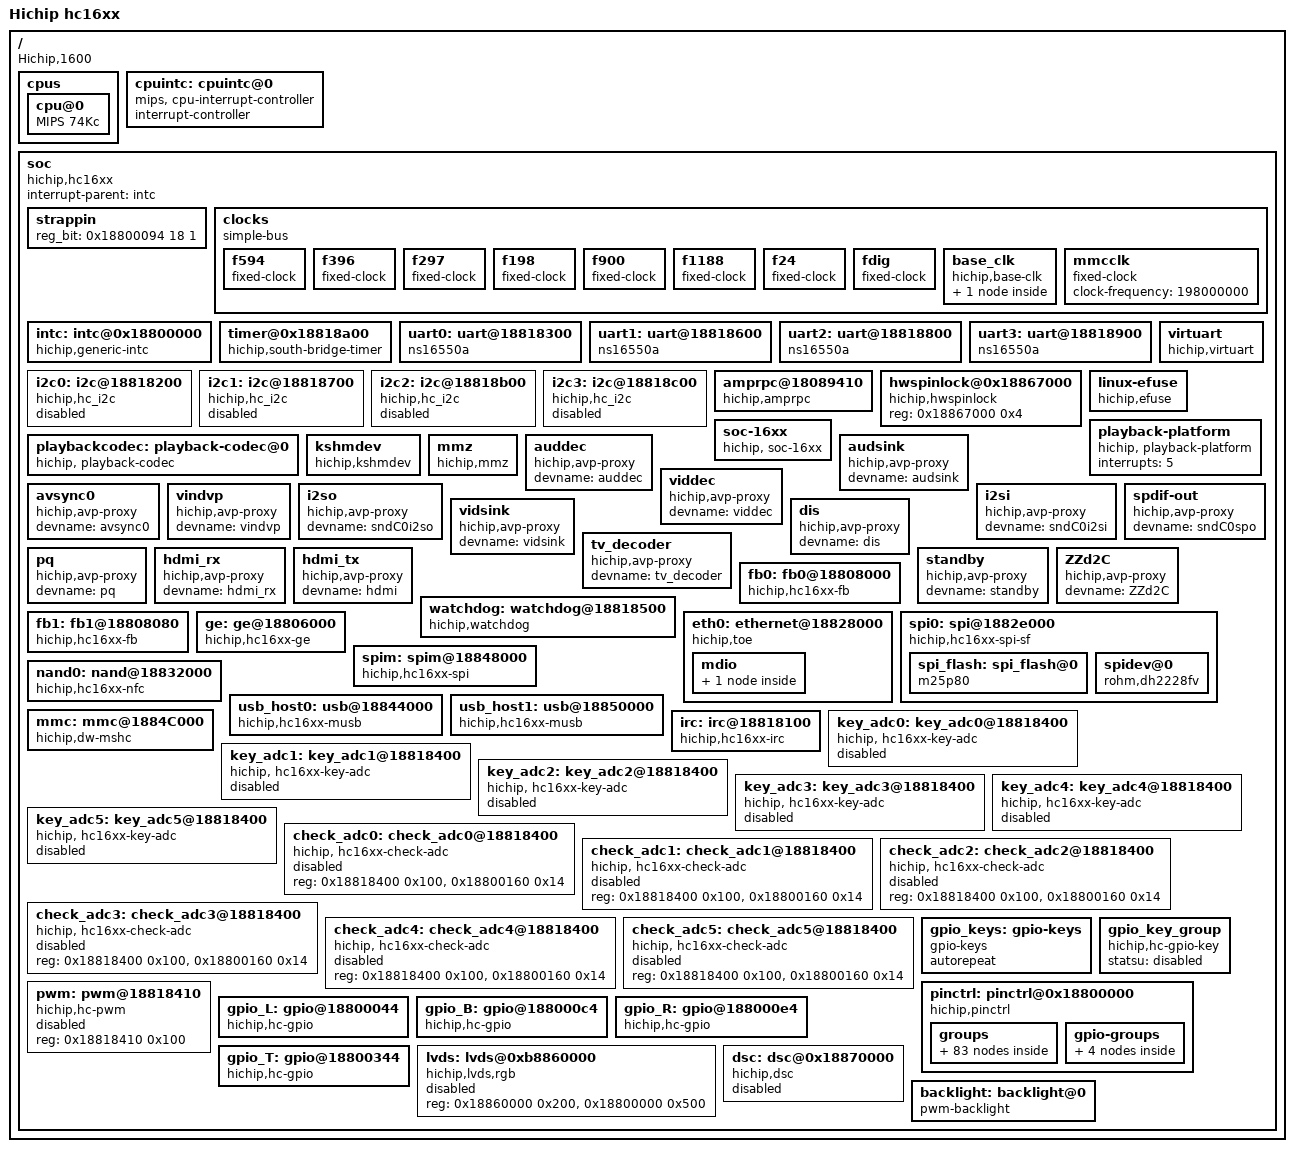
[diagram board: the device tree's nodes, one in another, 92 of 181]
/dts-v1/;

#include <dt-bindings/gpio/gpio.h>

#define MCPU_DIG_PLL_CLK 900

/{
	model = "Hichip hc16xx";
	compatible = "Hichip,1600";
	#address-cells = <1>;
	#size-cells = <1>;
	interrupt-parent = <&cpuintc>;

	cpus: cpus {
		#address-cells = <1>;
		#size-cells = <0>;
		cpu@0 {
			device_type = "cpu";
			compatible = "MIPS 74Kc";
			reg = <0>;
			clocks = <&cpu_clk>;
			/*
			 * 0 : 594M
			 * 1 : 396M
			 * 2 : 297M
			 * 3 : 198M
			 * 4 : 900M
			 * 5 : 1188M
			 * 6 : 24M
			 * 7 : CPU dig pll clk
			 */
			clock = <4>;
			mcpu-dig-pll-clk = <MCPU_DIG_PLL_CLK>;
		};
	};

	cpuintc: cpuintc@0 {
		#address-cells = <0>;
		#interrupt-cells = <1>;
		interrupt-controller;
		compatible = "mips, cpu-interrupt-controller";
	};

	

soc {
	#address-cells = <1>;
	#size-cells = <1>;
	device_type = "soc";
	ranges;
	compatible = "hichip,hc16xx", "simple-bus";
	interrupt-parent=<&intc>;

	strappin:strappin {
		device_type = "hichip,platform-setup-setbit";
		reg_bit = <0x18800094 18 1>;
	};

	clocks {
		#address-cells = <1>;
		#size-cells = <1>;
		compatible = "simple-bus";
		ranges;

		f594: f594 {
			#clock-cells = <0>;
			compatible = "fixed-clock";
			clock-frequency = <594000000>;
			clock-output-names="f594";
		};

		f396: f396 {
			#clock-cells = <0>;
			compatible = "fixed-clock";
			clock-frequency = <396000000>;
			clock-output-names="f396";
		};
		f297: f297 {
			#clock-cells = <0>;
			compatible = "fixed-clock";
			clock-frequency = <297000000>;
			clock-output-names="f297";
		};
		f198: f198 {
			#clock-cells = <0>;
			compatible = "fixed-clock";
			clock-frequency = <198000000>;
			clock-output-names="f198";
		};
		f900: f900 {
			#clock-cells = <0>;
			compatible = "fixed-clock";
			clock-frequency = <900000000>;
			clock-output-names="f900";
		};
		f1188: f1188 {
			#clock-cells = <0>;
			compatible = "fixed-clock";
			clock-frequency = <1188000000>;
			clock-output-names="f1188";
		};

		f24: f24 {
			#clock-cells = <0>;
			compatible = "fixed-clock";
			clock-frequency = <24000000>;
			clock-output-names="f24";
		};

		fdig: fdig {
			#clock-cells = <0>;
			compatible = "fixed-clock";
			clock-frequency = <(MCPU_DIG_PLL_CLK * 1000000)>;
			clock-output-names="fdig";
		};

		base_clk {
			compatible = "hichip,base-clk";
			#address-cells = <1>;
			#size-cells = <1>;
			ranges;

			cpu_clk: cpu_clk@18800070 {
				#clock-cells = <0>;
				compatible = "hichip,cpu-clk";
				reg = <0x18800074 0x4>, <0x18800070 0x4>;

				ctrl_shift = /bits/ 8 <8>;
				info_shift = /bits/ 8 <8>;
				trig_shift = /bits/ 8 <22>;
				width = /bits/ 8 <3>;

				clocks = <&f594>, <&f396>, <&f297>, <&f198>,
				       <&f900>, <&f1188>, <&f24>, <&fdig>;
				clock-output-names = "cpu_clk";
			};
		};

		mmcclk: mmcclk {
			#clock-cells = <0>;
			compatible = "fixed-clock";
			//clock-freq-min-max = <200000 150000000>;
			// clock-frequency = <298000000>;
			 clock-frequency = <198000000>;
			//clock-frequency = <150000000>;
			 //clock-frequency = <99000000>;
			 //clock-frequency = <49500000>;
		};
	};

	intc: intc@0x18800000 {
		compatible="hichip,generic-intc";
		interrupt-controller;
		#interrupt-cells=<1>;
		max-irqs = <96>;
		interrupt-parent = <&cpuintc>;
		interrupts = <3 2>;
		reg = <0x18800028 0x18>,
		      <0x18800030 0x18>,
		      <0x18800038 0x18>,
		      <0x18800020 0x18>;
	};

	timer@0x18818a00 {
		compatible = "hichip,south-bridge-timer";
		reg = <0x18818a00 0x100>;
		interrupts = <22>;
		clock-frequency = <24000000>;
	};

	uart0: uart@18818300 {
		compatible = "ns16550a";
		reg = <0x18818300 0x0C>;
		interrupts = <16>;
		clock-frequency = <1843200>;
		current-speed = <115200>;
		reg-offset = <0>;
		reg-shift = <0>;
		fifo-size = <16>;
		reg-io-width = <1>;
		device_type = "hichip,platform-setup-setbit";
		reg_bit = <0x18800060 16 0>, <0x18800094 18 1>;
	};

	uart1: uart@18818600 {
		compatible = "ns16550a";
		reg = <0x18818600 0x0C>;
		interrupts = <17>;
		clock-frequency = <1843200>;
		current-speed = <115200>;
		reg-offset = <0>;
		reg-shift = <0>;
		fifo-size = <16>;
		reg-io-width = <1>;
		device_type = "hichip,platform-setup-setbit";
		reg_bit = <0x18800060 17 0>;
	};

	uart2: uart@18818800 {
		compatible = "ns16550a";
		reg = <0x18818800 0x0C>;
		interrupts = <54>;
		clock-frequency = <1843200>;
		current-speed = <115200>;
		reg-offset = <0>;
		reg-shift = <0>;
		fifo-size = <16>;
		reg-io-width = <1>;
		device_type = "hichip,platform-setup-setbit";
		reg_bit = <0x18800064 11 0>;
	};

	uart3: uart@18818900 {
		compatible = "ns16550a";
		reg = <0x18818900 0x0C>;
		interrupts = <55>;
		clock-frequency = <1843200>;
		current-speed = <115200>;
		reg-offset = <0>;
		reg-shift = <0>;
		fifo-size = <16>;
		reg-io-width = <1>;
		device_type = "hichip,platform-setup-setbit";
		reg_bit = <0x18800064 11 0>;
	};

	i2c0: i2c@18818200 {
     		compatible = "hichip,hc_i2c";
		reg = <0x18818200 0x100>;
		master-mode = <1>;
		baud_speed = <100000>;
		interrupts = <18>;
		status = "disabled";
	};
	
	i2c1: i2c@18818700 {
     		compatible = "hichip,hc_i2c";
		reg = <0x18818700 0x100>;
		master-mode = <1>;
		baud_speed = <100000>;
		interrupts = <25>;
		status = "disabled";
	};

	i2c2: i2c@18818b00 {
     		compatible = "hichip,hc_i2c";
		reg = <0x18818b00 0x100>;
		master-mode = <1>;
		baud_speed = <100000>;
		interrupts = <26>;
		status = "disabled";
	};

	i2c3: i2c@18818c00 {                 
                compatible = "hichip,hc_i2c";
                reg = <0x18818c00 0x100>;    
                master-mode = <1>;           
                baud_speed = <100000>;       
		interrupts = <43>;
                status = "disabled";         
         };                                   

	amprpc@18089410 {
		compatible = "hichip,amprpc";
		interrupts = <66>;
		reg = <0x18800800 0x20>,
		      <0x18800820 0x20>,
		      <0x18800840 0x20>,
		      <0x18800860 0x20>,
		      <0x18800880 0x20>,
		      <0x188008a0 0x20>,
		      <0x188008c0 0x20>,
		      <0x188008e0 0x20>,
		      <0x18866800 0x20>,
		      <0x18866820 0x20>,
		      <0x18866840 0x20>,
		      <0x18866860 0x20>,
		      <0x18866880 0x20>,
		      <0x188668a0 0x20>,
		      <0x188668c0 0x20>,
		      <0x188668e0 0x20>;
	};


	hwspinlock@0x18867000 {
		compatible = "hichip,hwspinlock";
		reg = <0x18867000 0x4>;
	};

	virtuart {
		compatible = "hichip,virtuart";
	};

	linux-efuse {
		compatible = "hichip,efuse";
	};

	soc-16xx {
		compatible = "hichip, soc-16xx";
	};

	playback-platform {
		compatible = "hichip, playback-platform";
		interrupts = <5>;
	};

	playbackcodec: playback-codec@0 {
		compatible = "hichip, playback-codec";
	};
	/* for alsa end */

	kshmdev {
		compatible = "hichip,kshmdev";
	};

	mmz {
		compatible = "hichip,mmz";
	};

	/* for avp-proxy device driver start */
	auddec {
		compatible = "hichip,avp-proxy";
		devname = "auddec";
	};

	audsink {
		compatible = "hichip,avp-proxy";
		devname = "audsink";
	};

	viddec {
		compatible = "hichip,avp-proxy";
		devname = "viddec";
	};

	avsync0 {
		compatible = "hichip,avp-proxy";
		devname = "avsync0";
	};

	vindvp {
		compatible = "hichip,avp-proxy";
		devname = "vindvp";
	};

	i2so {
		compatible = "hichip,avp-proxy";
		devname = "sndC0i2so";
	};

	i2si {
		compatible = "hichip,avp-proxy";
		devname = "sndC0i2si";
	};

	spdif-out {
		compatible = "hichip,avp-proxy";
		devname = "sndC0spo";
	};

	vidsink {
		compatible = "hichip,avp-proxy";
		devname = "vidsink";
	};

	dis {
		compatible = "hichip,avp-proxy";
		devname = "dis";
	};

	tv_decoder {
		compatible = "hichip,avp-proxy";
		devname = "tv_decoder";
	};
	pq {
		compatible = "hichip,avp-proxy";
		devname = "pq";
	};

	hdmi_rx {
		compatible = "hichip,avp-proxy";
		devname = "hdmi_rx";
	};

	hdmi_tx {
		compatible = "hichip,avp-proxy";
		devname = "hdmi";
	};

	standby {
		compatible = "hichip,avp-proxy";
		devname = "standby";
	};

	ZZd2C {
		compatible = "hichip,avp-proxy";
		devname = "ZZd2C";
	};

	/* for avp-proxy device driver end */

	watchdog: watchdog@18818500 {
		compatible = "hichip,watchdog";
		reg = <0x18818500 0x0A>;
		interrupts = <23>;
		timeout-sec = <30>;
	};


	fb0: fb0@18808000 {
		compatible = "hichip,hc16xx-fb";
	};

	fb1: fb1@18808080 {
		compatible = "hichip,hc16xx-fb";
	};

    ge: ge@18806000 {
        compatible = "hichip,hc16xx-ge";
        reg = <0x18806000 0x2000>, <0x18800000 0x1000>;
        interrupts = <4>;
        cmdq_buf_size = <0x3c000>;
        status = "okay";
    };

	eth0: ethernet@18828000 {
		compatible = "hichip,toe";
		device_type = "network";
		model = "HiChip TOE";
		reg = <0x18828000 0x2000 0x18800000 0x4>;
		interrupts = <14>;
		rx-csum-enable = <1>;
		tx-csum-enable = <1>;
		phy-mode = "rmii";
		phy-reversemii = <0>;
		phy-handle = <&phy1>;

		mdio {
			#address-cells = <1>;
			#size-cells = <0>;
			status = "okay";
			phy1: ethernet-phy@1 {
				reg = <1>;
				device_type = "ethernet-phy";
			};
		};
	};

	spi0: spi@1882e000 {
		#address-cells = <1>;
		#size-cells = <0>;
		compatible = "hichip,hc16xx-spi-sf";
		reg = <0x1882e000 0xe0>, <0x1f000000 0x1000>, <0x1f000000 0x1000>;
		num-cs = <2>;
		interrupts = <35>;
		sclk = <50000000>;
		dma-mode = <1>;
		pinctrl-names = "active";
		pinctrl-0 = <&pctl_sf>;

		spi_flash: spi_flash@0 {
			#address-cells = <1>;
			#size-cells = <1>;
			compatible = "m25p80";
			reg = <0>;
			spi-max-frequency = <100000000>;
		};

		spidev@0 {
			compatible = "rohm,dh2228fv";
			reg = <1>;
			spi-max-frequency = <100000000>;
		};
	};


	spim: spim@18848000 {
		compatible = "hichip,hc16xx-spi";
		reg = <0x18848000 0x100>;
		clk_ratio = <4>;
		transfer-mode = <0>;
		dma-mode = <1>;
		cs-pin = <49>;
	};

	nand0: nand@18832000 {
		compatible = "hichip,hc16xx-nfc";
		reg = <0x18832000 0x60>;
		interrupts = <48>;
		scrambling = <0>;
		nand-on-flash-bbt;
		nand-ecc-mode = "hw";
		nand-ecc-algo = "bch";
	};

	usb_host0: usb@18844000 {  // usb_host0 / usb_peripheral0
		compatible = "hichip,hc16xx-musb";
		reg = <0x18844000 0x1000>;
		interrupts = <53>,<52>;
		interrupt-names = "mc","dma";
		dr_mode = "host";  // host/peripheral
		index_num = <0>;
		ctrl_base = <0x18800000>;
	};
	
	usb_host1: usb@18850000 {  // usb_host1/ usb_peripheral1
		compatible = "hichip,hc16xx-musb";
		reg = <0x18850000 0x1000>;
		interrupts = <51>,<50>;
		interrupt-names = "mc","dma";
		dr_mode = "host";
		index_num = <1>;
		ctrl_base = <0x18800000>;
	};

	mmc: mmc@1884C000 {
		compatible = "hichip,dw-mshc";
		// compatible = "snps,dw-mshc";
		reg = <0x1884C000 0x2000>;
		card-detect-delay = <200>;
		clocks = <&mmcclk>, <&mmcclk>;
		clock-names = "biu", "ciu";
		interrupts = <10>;
	};

	irc: irc@18818100 {
		compatible = "hichip,hc16xx-irc";
		reg = <0x18818100 0x60>;
		interrupts = <19>;
	};

	key_adc0: key_adc0@18818400 {
		compatible = "hichip, hc16xx-key-adc";
		reg = <0x18818400 0x100>, <0x18800160 0x14>;
		interrupts = <37>;
		status = "disabled";
	};

	key_adc1: key_adc1@18818400 {
		compatible = "hichip, hc16xx-key-adc";
		reg = <0x18818400 0x100>, <0x18800160 0x14>;
		interrupts = <37>;
		status = "disabled";
	};

	key_adc2: key_adc2@18818400 {
		compatible = "hichip, hc16xx-key-adc";
		reg = <0x18818400 0x100>, <0x18800160 0x14>;
		interrupts = <37>;
		status = "disabled";
	};

	key_adc3: key_adc3@18818400 {
		compatible = "hichip, hc16xx-key-adc";
		reg = <0x18818400 0x100>, <0x18800160 0x14>;
		interrupts = <37>;
		status = "disabled";
	};

	key_adc4: key_adc4@18818400 {
		compatible = "hichip, hc16xx-key-adc";
		reg = <0x18818400 0x100>, <0x18800160 0x14>;
		interrupts = <37>;
		status = "disabled";
	};

	key_adc5: key_adc5@18818400 {
		compatible = "hichip, hc16xx-key-adc";
		reg = <0x18818400 0x100>, <0x18800160 0x14>;
		interrupts = <37>;
		status = "disabled";
	};

	check_adc0: check_adc0@18818400 {
		compatible = "hichip, hc16xx-check-adc";
		reg = <0x18818400 0x100>, <0x18800160 0x14>;
		status = "disabled";
	};

	check_adc1: check_adc1@18818400 {
		compatible = "hichip, hc16xx-check-adc";
		reg = <0x18818400 0x100>, <0x18800160 0x14>;
		status = "disabled";
	};

	check_adc2: check_adc2@18818400 {
		compatible = "hichip, hc16xx-check-adc";
		reg = <0x18818400 0x100>, <0x18800160 0x14>;
		status = "disabled";
	};

	check_adc3: check_adc3@18818400 {
		compatible = "hichip, hc16xx-check-adc";
		reg = <0x18818400 0x100>, <0x18800160 0x14>;
		status = "disabled";
	};

	check_adc4: check_adc4@18818400 {
		compatible = "hichip, hc16xx-check-adc";
		reg = <0x18818400 0x100>, <0x18800160 0x14>;
		status = "disabled";
	};

	check_adc5: check_adc5@18818400 {
		compatible = "hichip, hc16xx-check-adc";
		reg = <0x18818400 0x100>, <0x18800160 0x14>;
		status = "disabled";
	};

	gpio_keys: gpio-keys {
		compatible = "gpio-keys";
		#address-cells = <1>;
		#size-cells = <0>;
		autorepeat;
	};

	pwm: pwm@18818410 {
		compatible = "hichip,hc-pwm";
		reg = <0x18818410 0x100>;
		status = "disabled";
	};

	gpio_key_group: gpio_key_group {
		compatible = "hichip,hc-gpio-key";
		statsu = "disabled";
	};

	pinctrl: pinctrl@0x18800000 {
		compatible = "hichip,pinctrl";
		reg = <0x18800000 0x820>;
		pins =
			"GPIO_L_00",	// pin 0
			"GPIO_L_01",	// pin 1
			"GPIO_L_02",	// pin 2
			"GPIO_L_03",	// pin 3
			"GPIO_L_04",	// pin 4
			"GPIO_L_05",	// pin 5
			"GPIO_L_06",	// pin 6
			"GPIO_L_07",	// pin 7
			"GPIO_L_08",	// pin 8
			"GPIO_L_09",	// pin 9
			"GPIO_L_10",	// pin 10
			"GPIO_L_11",	// pin 11
			"GPIO_L_12",	// pin 12
			"GPIO_L_13",	// pin 13
			"GPIO_L_14",	// pin 14
			"GPIO_L_15",	// pin 15
			"GPIO_L_16",	// pin 16
			"GPIO_L_17",	// pin 17
			"GPIO_L_18",	// pin 18
			"GPIO_L_19",	// pin 19
			"GPIO_L_20",	// pin 20
			"GPIO_L_21",	// pin 21
			"GPIO_L_22",	// pin 22
			"GPIO_L_23",	// pin 23
			"GPIO_L_24",	// pin 24
			"GPIO_L_25",	// pin 25
			"GPIO_L_26",	// pin 26
			"GPIO_L_27",	// pin 27
			"GPIO_L_28",	// pin 28
			"GPIO_L_29",	// pin 29
			"GPIO_L_30",	// pin 30
			"GPIO_L_31",	// pin 31
			"GPIO_B_00",	// pin 32
			"GPIO_B_01",	// pin 33
			"GPIO_B_02",	// pin 34
			"GPIO_B_03",	// pin 35
			"GPIO_B_04",	// pin 36
			"GPIO_B_05",	// pin 37
			"GPIO_B_06",	// pin 38
			"GPIO_B_07",	// pin 39
			"GPIO_B_08",	// pin 40
			"GPIO_B_09",	// pin 41
			"GPIO_B_10",	// pin 42
			"GPIO_B_11",	// pin 43
			"GPIO_B_12",	// pin 44
			"GPIO_B_13",	// pin 45
			"GPIO_B_14",	// pin 46
			"GPIO_B_15",	// pin 47
			"GPIO_B_16",	// pin 48
			"GPIO_B_17",	// pin 49
			"GPIO_B_18",	// pin 50
			"GPIO_B_19",	// pin 51
			"GPIO_B_20",	// pin 52
			"GPIO_B_21",	// pin 53
			"GPIO_B_22",	// pin 54
			"GPIO_B_23",	// pin 55
			"GPIO_B_24",	// pin 56
			"GPIO_B_25",	// pin 57
			"GPIO_B_26",	// pin 58
			"GPIO_B_27",	// pin 59
			"GPIO_B_28",	// pin 60
			"GPIO_B_29",	// pin 61
			"GPIO_B_30",	// pin 62
			"GPIO_B_31",	// pin 63
			"GPIO_R_00",	// pin 64
			"GPIO_R_01",	// pin 65
			"GPIO_R_02",	// pin 66
			"GPIO_R_03",	// pin 67
			"GPIO_R_04",	// pin 68
			"GPIO_R_05",	// pin 69
			"GPIO_R_06",	// pin 70
			"GPIO_R_07",	// pin 71
			"GPIO_R_08",	// pin 72
			"GPIO_R_09",	// pin 73
			"GPIO_R_10",	// pin 74
			"GPIO_R_11",	// pin 75
			"GPIO_R_12",	// pin 76
			"GPIO_R_13",	// pin 77
			"GPIO_R_14",	// pin 78
			"GPIO_R_15",	// pin 79
			"GPIO_R_16",	// pin 80
			"GPIO_R_17",	// pin 81
			"GPIO_R_18",	// pin 82
			"GPIO_R_19",	// pin 83
			"GPIO_R_20",	// pin 84
			"GPIO_R_21",	// pin 85
			"GPIO_R_22",	// pin 86
			"GPIO_R_23",	// pin 87
			"GPIO_R_24",	// pin 88
			"GPIO_R_25",	// pin 89
			"GPIO_R_26",	// pin 90
			"GPIO_R_27",	// pin 91
			"GPIO_R_28",	// pin 92
			"GPIO_R_29",	// pin 93
			"GPIO_R_30",	// pin 94
			"GPIO_R_31",	// pin 95
			"GPIO_T_00",	// pin 96
			"GPIO_T_01",	// pin 97
			"GPIO_T_02",	// pin 98
			"GPIO_T_03",	// pin 99
			"GPIO_T_04",	// pin 100
			"GPIO_T_05",	// pin 101
			"GPIO_T_06",	// pin 102
			"GPIO_T_07",	// pin 103
			"GPIO_T_08",	// pin 104
			"GPIO_T_09",	// pin 105
			"GPIO_T_10",	// pin 106
			"GPIO_T_11",	// pin 107
			"GPIO_T_12",	// pin 108
			"GPIO_T_13",	// pin 109
			"GPIO_T_14",	// pin 110
			"GPIO_T_15",	// pin 111
			"GPIO_T_16",	// pin 112
			"GPIO_T_17",	// pin 113
			"GPIO_T_18",	// pin 114
			"GPIO_T_19",	// pin 115
			"GPIO_T_20",	// pin 116
			"GPIO_T_21",	// pin 117
			"GPIO_T_22",	// pin 118
			"GPIO_T_23",	// pin 119
			"GPIO_T_24",	// pin 120
			"GPIO_T_25",	// pin 121
			"GPIO_T_26",	// pin 122
			"GPIO_T_27",	// pin 123
			"GPIO_T_28",	// pin 124
			"GPIO_T_29",	// pin 125
			"GPIO_T_30",	// pin 126
			"GPIO_T_31";	// pin 127

		groups {
			GPIO_L_00 {
				name = "GPIO_L_00";
				pins = <0>;
				reg-offset = <0x4a0>;
			};
			GPIO_L_01 {
				name = "GPIO_L_01";
				pins = <1>;
				reg-offset = <0x4a1>;
			};
			GPIO_L_02 {
				name = "GPIO_L_02";
				pins = <2>;
				reg-offset = <0x4a2>;
			};
			GPIO_L_03 {
				name = "GPIO_L_03";
				pins = <3>;
				reg-offset = <0x4a3>;
			};
			GPIO_L_04 {
				name = "GPIO_L_04";
				pins = <4>;
				reg-offset = <0x4a4>;
			};
			GPIO_L_05 {
				name = "GPIO_L_05";
				pins = <5>;
				reg-offset = <0x4a5>;
			};
			GPIO_L_06 {
				name = "GPIO_L_06";
				pins = <6>;
				reg-offset = <0x4a6>;
			};
			GPIO_L_07 {
				name = "GPIO_L_07";
				pins = <7>;
				reg-offset = <0x4a7>;
			};
			GPIO_L_08 {
				name = "GPIO_L_08";
				pins = <8>;
				reg-offset = <0x4a8>;
			};
			GPIO_L_09 {
				name = "GPIO_L_09";
				pins = <9>;
				reg-offset = <0x4a9>;
			};
			GPIO_L_10 {
				name = "GPIO_L_10";
				pins = <10>;
				reg-offset = <0x4aa>;
			};
			GPIO_L_11 {
				name = "GPIO_L_11";
				pins = <11>;
				reg-offset = <0x4ab>;
			};
			GPIO_L_12 {
				name = "GPIO_L_12";
				pins = <12>;
				reg-offset = <0x4ac>;
			};
			GPIO_L_13 {
				name = "GPIO_L_13";
				pins = <13>;
				reg-offset = <0x4ad>;
			};
			GPIO_L_14 {
				name = "GPIO_L_14";
				pins = <14>;
				reg-offset = <0x4ae>;
			};
			GPIO_L_15 {
				name = "GPIO_L_15";
				pins = <15>;
				reg-offset = <0x4af>;
			};
			GPIO_L_16 {
				name = "GPIO_L_16";
				pins = <16>;
				reg-offset = <0x4b0>;
			};
			GPIO_L_17 {
				name = "GPIO_L_17";
				pins = <17>;
				reg-offset = <0x4b1>;
			};
			GPIO_L_18 {
				name = "GPIO_L_18";
				pins = <18>;
				reg-offset = <0x4b2>;
			};
			GPIO_L_19 {
				name = "GPIO_L_19";
				pins = <19>;
				reg-offset = <0x4b3>;
			};
			GPIO_L_20 {
				name = "GPIO_L_20";
				pins = <20>;
				reg-offset = <0x4b4>;
			};

			GPIO_B_00 {
				name = "GPIO_B_00";
				pins = <32>;
				reg-offset = <0x4e0>;
			};
			GPIO_B_01 {
				name = "GPIO_B_01";
				pins = <33>;
				reg-offset = <0x4e1>;
			};
			GPIO_B_02 {
				name = "GPIO_B_02";
				pins = <34>;
				reg-offset = <0x4e2>;
			};
			GPIO_B_03 {
				name = "GPIO_B_03";
				pins = <35>;
				reg-offset = <0x4e3>;
			};
			GPIO_B_04 {
				name = "GPIO_B_04";
				pins = <36>;
				reg-offset = <0x4e4>;
			};
			GPIO_B_05 {
				name = "GPIO_B_05";
				pins = <37>;
				reg-offset = <0x4e5>;
			};
			GPIO_B_06 {
				name = "GPIO_B_06";
				pins = <38>;
				reg-offset = <0x4e6>;
			};
			GPIO_B_07 {
				name = "GPIO_B_07";
				pins = <39>;
				reg-offset = <0x4e7>;
			};
			GPIO_B_08 {
				name = "GPIO_B_08";
				pins = <40>;
				reg-offset = <0x4e8>;
			};
			GPIO_B_09 {
				name = "GPIO_B_09";
				pins = <41>;
				reg-offset = <0x4e9>;
			};
			GPIO_B_10 {
				name = "GPIO_B_10";
				pins = <42>;
				reg-offset = <0x4ea>;
			};
			GPIO_B_11 {
				name = "GPIO_B_11";
				pins = <43>;
				reg-offset = <0x4eb>;
			};
			GPIO_B_12 {
				name = "GPIO_B_12";
				pins = <44>;
				reg-offset = <0x4ec>;
			};
			GPIO_B_13 {
				name = "GPIO_B_13";
				pins = <45>;
				reg-offset = <0x4ed>;
			};
			GPIO_B_14 {
				name = "GPIO_B_14";
				pins = <46>;
				reg-offset = <0x4ee>;
			};
			GPIO_B_15 {
				name = "GPIO_B_15";
				pins = <47>;
				reg-offset = <0x4ef>;
			};
			GPIO_B_16 {
				name = "GPIO_B_16";
				pins = <48>;
				reg-offset = <0x4f0>;
			};
			GPIO_B_17 {
				name = "GPIO_B_17";
				pins = <49>;
				reg-offset = <0x4f1>;
			};
			GPIO_B_18 {
				name = "GPIO_B_18";
				pins = <50>;
				reg-offset = <0x4f2>;
			};
			GPIO_B_19 {
				name = "GPIO_B_19";
				pins = <51>;
				reg-offset = <0x4f3>;
			};
			GPIO_B_20 {
				name = "GPIO_B_20";
				pins = <52>;
				reg-offset = <0x4f4>;
			};
			GPIO_B_21 {
				name = "GPIO_B_21";
				pins = <53>;
				reg-offset = <0x4f5>;
			};
			GPIO_B_22 {
				name = "GPIO_B_22";
				pins = <54>;
				reg-offset = <0x4f6>;
			};
			GPIO_B_23 {
				name = "GPIO_B_23";
				pins = <55>;
				reg-offset = <0x4f7>;
			};
			GPIO_B_24 {
				name = "GPIO_B_24";
				pins = <56>;
				reg-offset = <0x4f8>;
			};
			GPIO_R_00 {
				name = "GPIO_R_00";
				pins = <64>;
				reg-offset = <0x520>;
			};
			GPIO_R_01 {
				name = "GPIO_R_01";
				pins = <65>;
				reg-offset = <0x521>;
			};
			GPIO_R_02 {
				name = "GPIO_R_02";
				pins = <66>;
				reg-offset = <0x522>;
			};
			GPIO_R_03 {
				name = "GPIO_R_03";
				pins = <67>;
				reg-offset = <0x523>;
			};
			GPIO_R_04 {
				name = "GPIO_R_04";
				pins = <68>;
				reg-offset = <0x524>;
			};
			GPIO_R_05 {
				name = "GPIO_R_05";
				pins = <69>;
				reg-offset = <0x525>;
			};
			GPIO_R_06 {
				name = "GPIO_R_06";
				pins = <70>;
				reg-offset = <0x526>;
			};
			GPIO_R_07 {
				name = "GPIO_R_07";
				pins = <71>;
				reg-offset = <0x527>;
			};
			GPIO_R_08 {
				name = "GPIO_R_08";
				pins = <72>;
				reg-offset = <0x528>;
			};
			GPIO_R_09 {
				name = "GPIO_R_09";
				pins = <73>;
				reg-offset = <0x529>;
			};
			GPIO_R_10 {
				name = "GPIO_R_10";
				pins = <74>;
				reg-offset = <0x52a>;
			};
			GPIO_T_00 {
				name = "GPIO_T_00";
				pins = <96>;
				reg-offset = <0x560>;
			};
			GPIO_T_01 {
				name = "GPIO_T_01";
				pins = <97>;
				reg-offset = <0x561>;
			};
			GPIO_T_02 {
				name = "GPIO_T_02";
				pins = <98>;
				reg-offset = <0x562>;
			};
			GPIO_T_03 {
				name = "GPIO_T_03";
				pins = <99>;
				reg-offset = <0x563>;
			};
			GPIO_T_04 {
				name = "GPIO_T_04";
				pins = <100>;
				reg-offset = <0x564>;
			};
			GPIO_T_05 {
				name = "GPIO_T_05";
				pins = <101>;
				reg-offset = <0x565>;
			};
			GPIO_T_06 {
				name = "GPIO_T_06";
				pins = <102>;
				reg-offset = <0x566>;
			};
			GPIO_T_07 {
				name = "GPIO_T_07";
				pins = <103>;
				reg-offset = <0x567>;
			};
			GPIO_T_08 {
				name = "GPIO_T_08";
				pins = <104>;
				reg-offset = <0x568>;
			};
			GPIO_T_09 {
				name = "GPIO_T_09";
				pins = <105>;
				reg-offset = <0x569>;
			};
			GPIO_T_10 {
				name = "GPIO_T_10";
				pins = <106>;
				reg-offset = <0x56a>;
			};
			GPIO_T_11 {
				name = "GPIO_T_11";
				pins = <107>;
				reg-offset = <0x56b>;
			};
			GPIO_T_12 {
				name = "GPIO_T_12";
				pins = <108>;
				reg-offset = <0x56c>;
			};
			GPIO_T_13 {
				name = "GPIO_T_13";
				pins = <109>;
				reg-offset = <0x56d>;
			};
			GPIO_T_14 {
				name = "GPIO_T_14";
				pins = <110>;
				reg-offset = <0x56e>;
			};
			GPIO_T_15 {
				name = "GPIO_T_15";
				pins = <111>;
				reg-offset = <0x56f>;
			};
			GPIO_T_16 {
				name = "GPIO_T_16";
				pins = <112>;
				reg-offset = <0x570>;
			};
			GPIO_T_17 {
				name = "GPIO_T_17";
				pins = <113>;
				reg-offset = <0x571>;
			};
			GPIO_T_18 {
				name = "GPIO_T_18";
				pins = <114>;
				reg-offset = <0x572>;
			};
			GPIO_T_19 {
				name = "GPIO_T_19";
				pins = <115>;
				reg-offset = <0x573>;
			};
			GPIO_T_20 {
				name = "GPIO_T_20";
				pins = <116>;
				reg-offset = <0x574>;
			};
			GPIO_T_21 {
				name = "GPIO_T_21";
				pins = <117>;
				reg-offset = <0x575>;
			};
			GPIO_T_22 {
				name = "GPIO_T_22";
				pins = <118>;
				reg-offset = <0x576>;
			};
			GPIO_T_23 {
				name = "GPIO_T_23";
				pins = <119>;
				reg-offset = <0x577>;
			};
			GPIO_T_24 {
				name = "GPIO_T_24";
				pins = <120>;
				reg-offset = <0x578>;
			};
			GPIO_T_25 {
				name = "GPIO_T_25";
				pins = <121>;
				reg-offset = <0x579>;
			};
		};

		gpio-groups {
			#address-cells = <1>;
			#size-cells = <1>;
			pctl_gpiol: GPIO_L@gpio-group1 {
				name = "GPIO_L";
				pins = <0 1 2 3 4 5 6 7 8 9 10 11 12 13 14 15 16 17 18 19 20 21 22 23 24 25 26 27 28 29 30 31>;
				reg = <0x188004a0 0x30>;
			};
			pctl_gpiob: GPIO_B@gpio-group2 {
				name = "GPIO_B";
				pins = <32 33 34 35 36 37 38 39 40 41 42 43 44 45 46 47 48 49 50 51 52 53 54 55 56 57 58 59 60 61 62 63>;
				reg = <0x188004e0 0x30>;
			};
			pctl_gpior: GPIO_R@gpio-group3 {
				name = "GPIO_R";
				pins = <64 65 66 67 68 69 70 71 72 73 74 75 76 77 78 79 80 81 82 83 84 85 86 87 88 89 90 91 92 93 94 95>;
				reg = <0x18800520 0x30>;
			};
			pctl_gpiot: GPIO_T@gpio-group4 {
				name = "GPIO_T";
				pins = <96 97 98 99 100 101 102 103 104 105 106 107 108 109 110 111 112 113 114 115 116 117 118 119 120 121 122 123 124 125 126 127>;
				reg = <0x18800560 0x30>;
			};
		 };
	};

	gpio_L: gpio@18800044 {
		compatible = "hichip,hc-gpio";
		reg = <0x18800044 0x1c>;
		interrupts = <0>;
		gpio-controller;
		#gpio-cells = <2>;
		ngpio = <32>;
		gpio-base = <0>;
		interrupt-parent=<&intc>;
		interrupt-controller;
		gpio-ranges = <&pinctrl 0 0 32>;
		#interrupt-cells = <1>;
	};

	gpio_B: gpio@188000c4 {
		compatible = "hichip,hc-gpio";
		reg = <0x188000c4 0x1c>;
		interrupts = <0>;
		gpio-controller;
		#gpio-cells = <2>;
		ngpio = <32>;
		gpio-base = <32>;
		interrupt-parent=<&intc>;
		interrupt-controller;
		gpio-ranges = <&pinctrl 0 32 32>;
		#interrupt-cells = <1>;
	};

	gpio_R: gpio@188000e4 {
		compatible = "hichip,hc-gpio";
		reg = <0x188000e4 0x1c>;
		interrupts = <0>;
		gpio-controller;
		#gpio-cells = <2>;
		ngpio = <32>;
		gpio-base = <64>;
		interrupt-parent=<&intc>;
		interrupt-controller;
		gpio-ranges = <&pinctrl 0 64 32>;
		#interrupt-cells = <1>;
	};

	gpio_T: gpio@18800344 {
		compatible = "hichip,hc-gpio";
		reg = <0x18800344 0x1c>;
		interrupts = <0>;
		gpio-controller;
		#gpio-cells = <2>;
		ngpio = <32>;
		gpio-base = <96>;
		interrupt-parent=<&intc>;
		interrupt-controller;
		gpio-ranges = <&pinctrl 0 96 32>;
		#interrupt-cells = <1>;
	};

	lvds: lvds@0xb8860000 {
		compatible = "hichip,lvds,rgb";
		reg = <0x18860000 0x200>, <0x18800000 0x500>;
		status = "disabled";
	};

	dsc: dsc@0x18870000 {
		compatible = "hichip,dsc";
		/*reg = <0x18870000 0x1000>;*/
		reg = <0x18834000 0x1000>;

		/* dsc initialize maloc memory size,
		* such as <0x100000 0x80000>, dsc maloc tow memory cache, 
		* every cache size is 1MBytes, and 512Kbytes.
		*/
		memory-cache-node = <0>;
		interrupts = <44>;
		status = "disabled";
	};

	backlight:backlight@0 {
		compatible = "pwm-backlight";
	};
};
};
